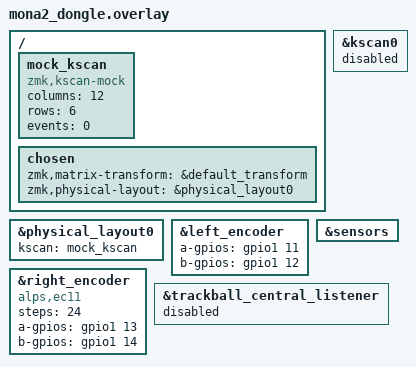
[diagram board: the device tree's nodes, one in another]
#include "mona2.dtsi"

/ {
    // 【最大の解決策】ZMKのサイズチェックをパスさせるための「大きな器」
    // 12列×6行のダミーを用意することで、起動時のサイレントクラッシュを完全に防ぎます！
    mock_kscan: mock_kscan {
        compatible = "zmk,kscan-mock";
        columns = <12>;
        rows = <6>;
        events = <0>;
    };

    chosen {
        // ペリフェラルからのBluetooth信号（行列データ）を変換するために必須
        zmk,matrix-transform = &default_transform;
        // ZMK Studioやキーマップの要となる物理レイアウト
        zmk,physical-layout = &physical_layout0;
        
        // ※ zmk,kscan は xiaord.overlay が自動で上書きするためここでは省略します
    };
};

// 既存の物理レイアウトに、十分な大きさのダミー枠を紐付けます
&physical_layout0 {
    kscan = <&mock_kscan>;
};

// 元の物理キーマトリクスは無効化
&kscan0 {
    status = "disabled";
};

// エンコーダーをダミーピンに逃がし、ディスプレイ競合を完全防止
&left_encoder {
    status = "okay";
    a-gpios = <&gpio1 11 (GPIO_ACTIVE_HIGH | GPIO_PULL_UP)>;
    b-gpios = <&gpio1 12 (GPIO_ACTIVE_HIGH | GPIO_PULL_UP)>;
};

&right_encoder {
    status = "okay";
    compatible = "alps,ec11";
    steps = <24>;
    a-gpios = <&gpio1 13 (GPIO_ACTIVE_HIGH | GPIO_PULL_UP)>;
    b-gpios = <&gpio1 14 (GPIO_ACTIVE_HIGH | GPIO_PULL_UP)>;
};

// センサーシステムはONのまま維持（キーマップクラッシュ防止）
&sensors {
    status = "okay";
};

// トラックボールのパニックエラーを防ぐため無効化
&trackball_central_listener {
    status = "disabled";
};
